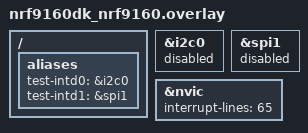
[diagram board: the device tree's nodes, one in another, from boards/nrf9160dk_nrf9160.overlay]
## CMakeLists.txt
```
# Copyright (c) 2024 Bjarki Arge Andreasen
# SPDX-License-Identifier: Apache-2.0

cmake_minimum_required(VERSION 3.20.0)
find_package(Zephyr REQUIRED HINTS $ENV{ZEPHYR_BASE})
project(test_sys_irq_irq)

target_sources(app PRIVATE src/test.c)
```

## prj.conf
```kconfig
# Copyright (c) 2024 Bjarki Arge Andreasen
# SPDX-License-Identifier: Apache-2.0

CONFIG_ZTEST=y
CONFIG_ZTEST_FAIL_FAST=y
```

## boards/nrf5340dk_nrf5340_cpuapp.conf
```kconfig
# Copyright (c) 2024 Nordic Semiconductor
# SPDX-License-Identifier: Apache-2.0

CONFIG_GEN_ISR_TABLES=n
```

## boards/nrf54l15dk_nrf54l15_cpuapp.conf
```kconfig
# Copyright (c) 2025 Nordic Semiconductor
# SPDX-License-Identifier: Apache-2.0

CONFIG_GEN_ISR_TABLES=n
```

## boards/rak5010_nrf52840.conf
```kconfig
# Copyright (c) 2024 Nordic Semiconductor
# SPDX-License-Identifier: Apache-2.0

CONFIG_GEN_ISR_TABLES=n
CONFIG_GEN_IRQ_VECTOR_TABLE=n
CONFIG_INTC=y
CONFIG_SYS_IRQ=y
```

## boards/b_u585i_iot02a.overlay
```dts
/*
 * Copyright (c) 2024 Bjarki Arge Andreasen
 *
 * SPDX-License-Identifier: Apache-2.0
 */

/ {
	aliases {
		test-intd0 = &spi1;
		test-intd1 = &spi2;
	};

	soc
};

&spi1 {
	status = "reserved";
};

&spi2 {
	status = "reserved";
};

&nvic {
	interrupt-lines = <128>;
};
```

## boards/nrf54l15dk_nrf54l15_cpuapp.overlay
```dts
/*
 * Copyright (c) 2025 Nordic Semiconductor
 *
 * SPDX-License-Identifier: Apache-2.0
 */

/ {
	aliases {
		test-intd0 = &timer20;
		test-intd1 = &timer21;
	};
};

&timer20 {
	status = "reserved";
};

&timer21 {
	status = "reserved";
};
```

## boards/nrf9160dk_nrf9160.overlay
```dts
/*
 * Copyright (c) 2024 Bjarki Arge Andreasen
 *
 * SPDX-License-Identifier: Apache-2.0
 */

/ {
	aliases {
		test-intd0 = &i2c0;
		test-intd1 = &spi1;
	};
};

&i2c0 {
	status = "reserved";
};

&spi1 {
	status = "reserved";
};

&nvic {
	interrupt-lines = <65>;
};
```

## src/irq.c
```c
/*
 * Copyright (c) 2024 Bjarki Arge Andreasen
 *
 * SPDX-License-Identifier: Apache-2.0
 */

#include <zephyr/sys/irq.h>
#include <zephyr/kernel.h>
#include <zephyr/ztest.h>

#define TEST_IRQ_MAX_DELAY K_MSEC(10)

#define INTD0_NODE DT_ALIAS(test_intd0)
#define INTD1_NODE DT_ALIAS(test_intd1)

#define INTD0_SYS_IRQN SYS_DT_IRQN(INTD0_NODE)
#define INTD1_SYS_IRQN SYS_DT_IRQN(INTD1_NODE)

#define INTD0_IRQ_FLAGS SYS_DT_IRQ_FLAGS(INTD0_NODE)
#define INTD1_IRQ_FLAGS SYS_DT_IRQ_FLAGS(INTD1_NODE)

BUILD_ASSERT(INTD0_SYS_IRQN != INTD1_SYS_IRQN, "INTDs must not share INTL");
BUILD_ASSERT(DT_NODE_HAS_STATUS(INTD0_NODE, reserved), "INTD0 must have status reserved");
BUILD_ASSERT(DT_NODE_HAS_STATUS(INTD1_NODE, reserved), "INTD1 must have status reserved");

static K_SEM_DEFINE(irq0_sem, 0, 1);
static K_SEM_DEFINE(irq1_sem, 0, 1);

static uint32_t irq0_data;
static uint32_t irq1_data;

static int irq0_handler(const void *data)
{
	zassert_equal(data, &irq0_data);
	k_sem_give(&irq0_sem);
	return SYS_IRQ_HANDLED;
}

static int irq1_handler(const void *data)
{
	zassert_equal(data, &irq1_data);
	k_sem_give(&irq1_sem);
	return SYS_IRQ_HANDLED;
}

SYS_DT_DEFINE_IRQ_HANDLER(INTD0_NODE, irq0_handler, &irq0_data);
SYS_DT_DEFINE_IRQ_HANDLER(INTD1_NODE, irq1_handler, &irq1_data);

ZTEST(sys_irq_irq, test__trigger_irq_while_disabled__no_irq)
{
	zassert_ok(sys_irq_trigger(INTD0_SYS_IRQN));
	zassert_equal(k_sem_take(&irq0_sem, TEST_IRQ_MAX_DELAY), -EAGAIN);
	zassert_ok(sys_irq_trigger(INTD1_SYS_IRQN));
	zassert_equal(k_sem_take(&irq1_sem, TEST_IRQ_MAX_DELAY), -EAGAIN);
}

ZTEST(sys_irq_irq, test__trigger_irq_while_enabled__irq)
{
	zassert_ok(sys_irq_enable(INTD0_SYS_IRQN));
	zassert_equal(k_sem_take(&irq0_sem, TEST_IRQ_MAX_DELAY), -EAGAIN);
	zassert_ok(sys_irq_enable(INTD1_SYS_IRQN));
	zassert_equal(k_sem_take(&irq1_sem, TEST_IRQ_MAX_DELAY), -EAGAIN);
	zassert_ok(sys_irq_trigger(INTD0_SYS_IRQN));
	zassert_equal(k_sem_take(&irq0_sem, TEST_IRQ_MAX_DELAY), 0);
	zassert_ok(sys_irq_trigger(INTD1_SYS_IRQN));
	zassert_equal(k_sem_take(&irq1_sem, TEST_IRQ_MAX_DELAY), 0);
}

ZTEST(sys_irq_irq, test__disable_disabled_irq__retval_0)
{
	zassert_equal(sys_irq_disable(INTD0_SYS_IRQN), 0);
	zassert_equal(sys_irq_disable(INTD1_SYS_IRQN), 0);
}

ZTEST(sys_irq_irq, test__disable_enabled_irq__retval_1)
{
	zassert_ok(sys_irq_enable(INTD0_SYS_IRQN));
	zassert_ok(sys_irq_enable(INTD1_SYS_IRQN));
	zassert_equal(sys_irq_disable(INTD0_SYS_IRQN), 1);
	zassert_equal(sys_irq_disable(INTD1_SYS_IRQN), 1);
}

ZTEST(sys_irq_irq, test__clear_cleared_irq__retval_0)
{
	zassert_equal(sys_irq_clear(INTD0_SYS_IRQN), 0);
	zassert_equal(sys_irq_clear(INTD1_SYS_IRQN), 0);
}

ZTEST(sys_irq_irq, test__clear_triggered_irq__retval_1)
{
	zassert_ok(sys_irq_trigger(INTD0_SYS_IRQN));
	zassert_ok(sys_irq_trigger(INTD1_SYS_IRQN));
	zassert_equal(sys_irq_clear(INTD0_SYS_IRQN), 1);
	zassert_equal(sys_irq_clear(INTD1_SYS_IRQN), 1);
}

void *test_init(void)
{
	zassert_ok(sys_irq_configure(INTD0_SYS_IRQN, INTD0_IRQ_FLAGS));
	zassert_equal(k_sem_take(&irq0_sem, TEST_IRQ_MAX_DELAY), -EAGAIN);
	zassert_ok(sys_irq_configure(INTD1_SYS_IRQN, INTD1_IRQ_FLAGS));
	zassert_equal(k_sem_take(&irq1_sem, TEST_IRQ_MAX_DELAY), -EAGAIN);
	zassert_ok(sys_irq_trigger(INTD0_SYS_IRQN));
	zassert_equal(k_sem_take(&irq0_sem, TEST_IRQ_MAX_DELAY), -EAGAIN);
	zassert_ok(sys_irq_trigger(INTD1_SYS_IRQN));
	zassert_equal(k_sem_take(&irq1_sem, TEST_IRQ_MAX_DELAY), -EAGAIN);
	return NULL;
}

void test_before(void *f)
{
	ARG_UNUSED(f);

	zassert(sys_irq_disable(INTD0_SYS_IRQN) > -1, "retval must be positive");
	zassert(sys_irq_disable(INTD1_SYS_IRQN) > -1, "retval must be positive");
	zassert(sys_irq_clear(INTD0_SYS_IRQN) > -1, "retval must be positive");
	zassert(sys_irq_clear(INTD1_SYS_IRQN) > -1, "retval must be positive");
	k_sem_reset(&irq0_sem);
	k_sem_reset(&irq1_sem);
}

ZTEST_SUITE(sys_irq_irq, NULL, test_init, test_before, NULL, NULL);
```
